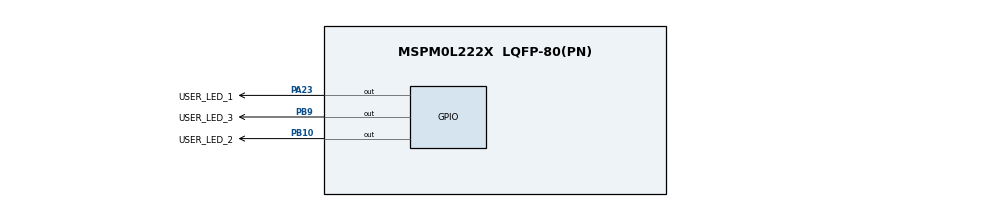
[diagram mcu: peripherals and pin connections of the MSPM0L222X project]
// @cliArgs --device "MSPM0L222X" --package "LQFP-80(PN)" --part "Default"
// @cliArgs --board /ti/boards/LP_MSPM0L2228 --rtos nortos

/**
 * Import the modules used in this configuration.
 */
const GPIO   = scripting.addModule("/ti/driverlib/GPIO", {}, false);
const GPIO1  = GPIO.addInstance();

/**
 * Write custom configuration values to the imported modules.
 */

GPIO1.$name                         = "GPIO_LEDS";
GPIO1.associatedPins.create(3);
GPIO1.associatedPins[0].$name       = "USER_LED_1";
GPIO1.associatedPins[0].pin.$assign = "PA23";
GPIO1.associatedPins[1].$name       = "USER_LED_2";
GPIO1.associatedPins[1].pin.$assign = "PB10";
GPIO1.associatedPins[2].$name       = "USER_LED_3";
GPIO1.associatedPins[2].pin.$assign = "PB9";

const SYSCTL = scripting.addModule("/ti/driverlib/SYSCTL");

SYSCTL.clockTreeEn = true;
